# LPC11xxLV_LPC111x_LV register map
File version: 1
LPC11xxLV
CPU: CM0 r0p0, little endian, no MPU, no FPU, 2 interrupt priority bits
Registers are 32-bit, read-write, reset 0x0 unless marked. A register's access mark holds for its fields unless they carry their own. Offsets are from the block's base; lines under a group give offsets from that group; [hi:lo] are bit positions; {n}, {i} and the like mark numbered series; 'fields as' and 'values as' point back to an identical list; <NAME> marks a mode.

## Memory map
0x40000000 I2C size 0x1000
0x40004000 WWDT size 0x1000 — Windowed WatchDog Timer (WDT)
0x40008000 UART size 0x1000
0x4000C000 CT16B0 size 0x1000 — 16-bit counter/timer CT16B0/1
0x40010000 CT16B1 size 0x1000
0x40014000 CT32B0 size 0x1000 — 32-bit counter/timer CT32B0/1
0x40018000 CT32B1 size 0x1000 — 32-bit counter/timer CT32B0/1
0x4001C000 ADC size 0x1000 — 10-bit ADC
0x4003C000 FLASHCTRL size 0x1000 — Flash controller
0x40040000 SPI0 size 0x1000
0x40044000 IOCON size 0x1000 — I/O configuration (IOCONFIG)
0x40048000 SYSCON size 0x1000 — System configuration (SYSCON)
0x50000000 GPIO0 size 0x10000
0x50010000 GPIO1 size 0x10000
0x50020000 GPIO2 size 0x10000
0x50030000 GPIO3 size 0x10000

## Interrupts
{n} PIO0_{n} (SYSCON) (n=0..11)
12 PIO1_0 (SYSCON)
15 I2C
16 CT16B0
17 CT16B1
18 CT32B0
19 CT32B1
20 SPI0
21 UART
24 ADC
25 WDT (WWDT)
26 BOD (SYSCON)
27 FMC (FLASHCTRL)
28 GPIO3
29 GPIO2
30 GPIO1
31 GPIO0

## WWDT — Windowed WatchDog Timer (WDT)
Base 0x40004000
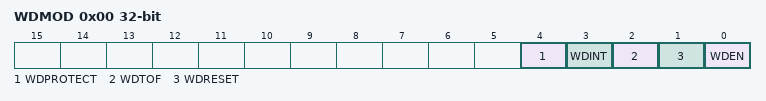
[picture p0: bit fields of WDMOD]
0x00 WDMOD — Watchdog mode register. This register contains the basic mode and status of the Watchdog Timer.
  [4] WDPROTECT — Watchdog update mode. This bit is Set Only.
    0=ANYTIME (The watchdog reload value (WDTC) can be changed at any time.); 1=LOWCOUNTER (The watchdog reload value (WDTC) can be changed only after the counter is below the value of WDWARNINT and WDWINDOW. Note: this mode is intended for use only when WDRESET =1.)
  [3] WDINT — Watchdog interrupt flag. Set when the timer reaches the value in WDWARNINT. Cleared by software.
  [2] WDTOF — Watchdog time-out flag. Set when the watchdog timer times out, by a feed error, or by events associated with WDPROTECT, cleared by software. Causes a chip reset if WDRESET = 1.
  [1] WDRESET — Watchdog reset enable bit. This bit is Set Only.
    0=NORESET (A watchdog timeout will not cause a chip reset.); 1=RESET (A watchdog timeout will cause a chip reset.)
  [0] WDEN — Watchdog enable bit. This bit is Set Only. Setting this bit to one also locks the watchdog clock source. Once the watchdog timer is enabled, the watchdog timer clock source cannot be changed. If the watchdog timer is needed in Deep-sleep mode, the watchdog clock source must be changed to the watchdog oscillator before setting this bit to one.
    0=STOPPED (The watchdog timer is stopped.); 1=RUN (The watchdog timer is running.)
0x04 WDTC reset 0xFF — Watchdog timer constant register. This register determines the time-out value.
  [23:0] Count — Watchdog time-out interval.
0x08 WDFEED wo reset not defined — Watchdog feed sequence register. Writing 0xAA followed by 0x55 to this register reloads the Watchdog timer with the value contained in WDTC.
  [7:0] Feed — Feed value should be 0xAA followed by 0x55.
0x0C WDTV ro reset 0xFF — Watchdog timer value register. This register reads out the current value of the Watchdog timer.
  [23:0] Count — Counter timer value.
0x14 WDWARNINT — Watchdog Warning Interrupt compare value.
  [9:0] WARNINT — Watchdog warning interrupt compare value.
0x18 WDWINDOW reset 0xFFFFFF — Watchdog Window compare value.
  [23:0] WINDOW — Watchdog window value.

## FLASHCTRL — Flash controller
Base 0x4003C000
0x10 FLASHCFG reset not defined — Flash memory access time configuration register
  [1:0] FLASHTIM — Flash memory access time. FLASHTIM +1 is equal to the number of system clocks used for flash access.
    1=1_SYSTEM_CLOCK_FLASH (1 system clock flash access time (for system clock frequencies of up to 20 MHz).); 2=2_SYSTEM_CLOCKS_FLAS (2 system clocks flash access time (for system clock frequencies of up to 40 MHz).); 3=3_SYSTEM_CLOCKS_FLAS (3 system clocks flash access time (for system clock frequencies of up to 50 MHz).)
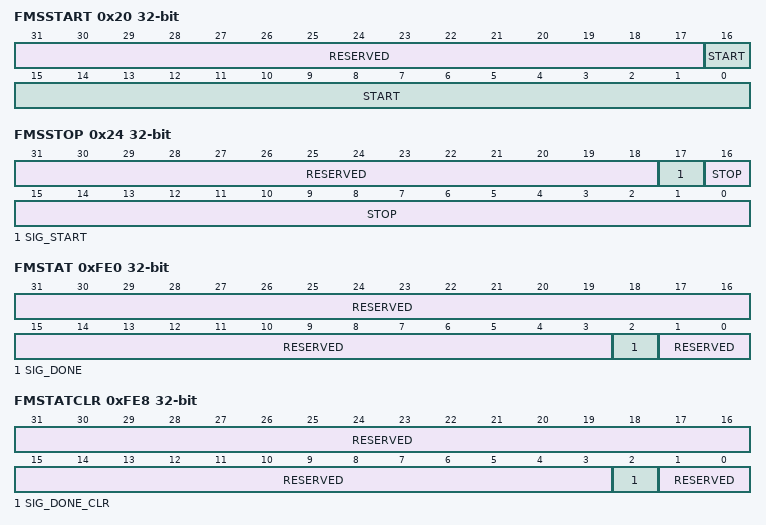
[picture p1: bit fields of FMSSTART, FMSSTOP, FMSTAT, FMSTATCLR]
0x20 FMSSTART — Signature start address register
  [31:17] RESERVED — Reserved, user software should not write ones to reserved bits. The value read from a reserved bit is not defined.
  [16:0] START — Signature generation start address (corresponds to AHB byte address bits[20:4]).
0x24 FMSSTOP — Signature stop-address register
  [31:18] RESERVED — Reserved, user software should not write ones to reserved bits. The value read from a reserved bit is not defined.
  [17] SIG_START — Start control bit for signature generation.
    0=SIGNATURE_GENERATION (Signature generation is stopped); 1=INITIATE_SIGNATURE_G (Initiate signature generation)
  [16:0] STOP — BIST stop address divided by 16 (corresponds to AHB byte address [20:4]).
{0x2C+4i} FMSW{i} ro reset not defined (i=0..3) — Word {i} [{32i+31}:{32i}]
  [31:0] SW{i}_{32i+31}_{32i} — Word {i} of 128-bit signature (bits {32i+31} to {32i}).
0xFE0 FMSTAT ro — Signature generation status register
  [31:3] RESERVED — Reserved, user software should not write ones to reserved bits. The value read from a reserved bit is not defined.
  [2] SIG_DONE — When 1, a previously started signature generation has completed. See FMSTATCLR register description for clearing this flag.
  [1:0] RESERVED — Reserved, user software should not write ones to reserved bits. The value read from a reserved bit is not defined.
0xFE8 FMSTATCLR wo reset not defined — Signature generation status clear register
  [31:3] RESERVED — Reserved, user software should not write ones to reserved bits. The value read from a reserved bit is not defined.
  [2] SIG_DONE_CLR — Writing a 1 to this bits clears the signature generation completion flag (SIG_DONE) in the FMSTAT register.
  [1:0] RESERVED — Reserved, user software should not write ones to reserved bits. The value read from a reserved bit is not defined.
